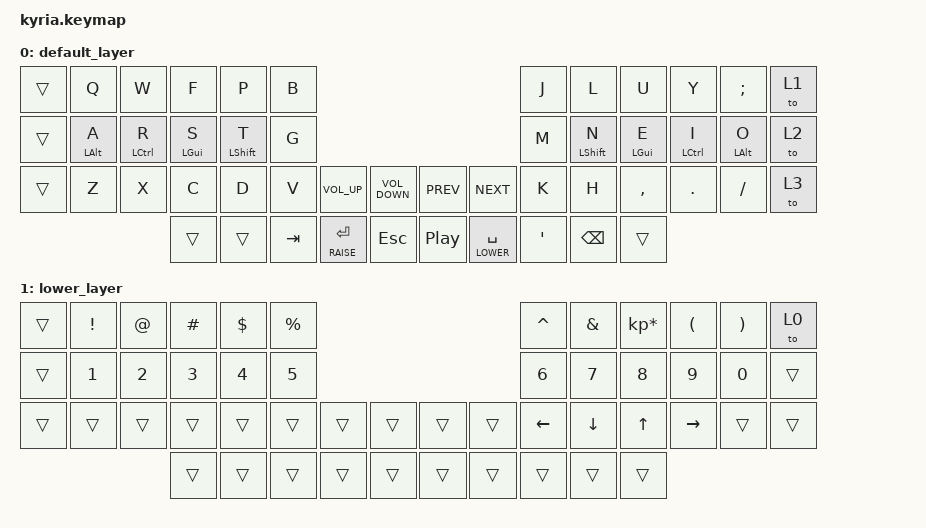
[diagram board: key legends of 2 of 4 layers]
#include <behaviors.dtsi>
#include <dt-bindings/zmk/keys.h>
#include <dt-bindings/zmk/bt.h>
#include <dt-bindings/zmk/outputs.h>
#include <dt-bindings/zmk/rgb.h>
#include <dt-bindings/zmk/ext_power.h>

#define DEFAULT 0
#define LOWER   1
#define RAISE   2
#define SETTINGS 3

# define BT(n) BT_SEL n

/ {
    behaviors {
        hm: homerow_mods {
            compatible = "zmk,behavior-hold-tap";
            label = "HOMEROW_MODS";
            #binding-cells = <2>;
            tapping_term_ms = <145>;
            flavor = "tap-preferred";
            bindings = <&kp>, <&kp>;
        };
    };

    combos {
        compatible = "zmk,combos";
        combo_bracket_curly_open {
            timeout-ms = <50>;
            key-positions = <14 15>;
            bindings = <&kp LBRC>;
        };
        // st is a bit too common as an inward roll to use for a combo
        combo_bracket_curly_close {
            timeout-ms = <50>;
            key-positions = <15 16>;
            bindings = <&kp RBRC>;
        };
    };

	keymap {
		compatible = "zmk,keymap";

		default_layer {
// ---------------------------------------------------------------------------------------------------------------------------------
// |  TAB  |  Q  |  W  |  F   |  P   |  B   |                                          |  J   |  L    |  U    |  Y   |   P   | ";"  |
// |  CTL  |  A  |  R  |  S   |  T   |  G   |                                          |  M   |  N    |  E    |  I   |   O   |   '  |
// | SHIFT |  Z  |  X  |  C   |  D   |  V   | L SHIFT | L SHIFT |  | L SHIFT | L SHIFT |  K   |  H    |  ,    |  .   |   /   | CTRL |
//                     | DEL  | GUI  | RET  |  SPACE  |  LOWER  |  |  RAISE  |  SPACE  | TAB  | BSPC  | R-ALT |
			bindings = <
	&trans  &kp Q       &kp W           &kp F       &kp P           &kp B                                                                           &kp J       &kp L       &kp U       &kp Y       &kp SEMI    &to 1
	&trans  &hm LALT A  &hm LCTRL R     &hm LGUI S  &hm LSHFT T     &kp G                                                                           &kp M       &hm LSHFT N &hm LGUI E  &hm LCTRL I &hm LALT O  &to 2
	&trans  &kp Z       &kp X           &kp C       &kp D           &kp V           &kp C_VOL_UP    &kp C_VOLUME_DOWN   &kp C_PREV  &kp C_NEXT      &kp K       &kp H       &kp COMMA   &kp DOT     &kp FSLH    &to 3
                                        &trans      &trans          &kp TAB         &lt RAISE RET   &kp ESC             &kp C_PP    &lt LOWER SPACE &kp SQT     &kp BSPC    &trans
			>;

            sensor-bindings = <&inc_dec_kp C_VOL_UP C_VOL_DN &inc_dec_kp PG_UP PG_DN>;
		};

		lower_layer {
// ---------------------------------------------------------------------------------------------------------------------------------
// |    |  !  |  @  |  #   |   $  |   %  |                 ~                    |  ^   |  &    |  * | (  |  )   |      |
// |    |  1  |  2  |  3   |  4   |  5   |                                      |  6   |  7    | 8  | 9  |  0   |      |
// |    |     |     |      |      |      |                                      |  ⬅   |  ⬇    | ⬆  | ➡  |      |      |
//                  |      |      |      |      |        |  |      |      |     |      |       |

// TODO: rearrange numbers to numpad layout
			bindings = <
    &trans &kp EXCL &kp AT  &kp HASH    &kp DLLR    &kp PRCNT                               &kp CARET   &kp AMPS    &kp KP_MULTIPLY &kp LPAR    &kp RPAR    &to 0
	&trans &kp N1   &kp N2  &kp N3      &kp N4      &kp N5                                  &kp N6      &kp N7      &kp N8          &kp N9      &kp N0      &trans
	&trans &trans   &trans  &trans      &trans      &trans    &trans &trans &trans &trans   &kp LEFT    &kp DOWN    &kp UP          &kp RIGHT  &trans       &trans
	                        &trans      &trans      &trans    &trans &trans &trans &trans   &trans      &trans      &trans
			>;
		};
        
		raise_layer {
// ---------------------------------------------------------------------------------------------------------------------------------
// |      |     |     |     |     |     |                 ~            |     |     |     |     |     |      |
// | CTRL |     |     |     |     |     |                 ~            |  -  |  =  |  {  |  }  | "|" |  `   |
// | SHFT |     |     |     |     |     |      |        | ~ |     |    |  _  |  +  |  [  |  ]  |  \  |  ~   | // TODO: Fix this row when &mkp is committed
//                 |      |      |      |      |        | ~ |     |    |     |     |     |
			bindings = <
    &trans   &kp EXCL &kp AT   &kp HASH &kp DLLR  &kp PRCNT                                 &kp CARET   &kp AMPS  &trans     &kp LPAR &kp RPAR &trans
    &kp BSLH &kp PLUS &kp LBRC &kp RBRC &kp TILDE &kp UNDER                                 &kp MINUS   &kp EQUAL &kp LBKT  &kp RBKT &kp PIPE &to 0
	&kp F1   &kp F2   &kp F3   &kp F4   &kp F5    &kp F6    &trans &trans &trans &trans     &kp F7      &kp F8    &kp F9    &kp F10  &kp F11  &kp F12
                               &trans   &to 3     &trans    &trans &trans &trans &kp GRAVE  &trans      &trans    &trans    &trans   &trans 
			>;
		};

        settings_layer {
        bindings = <
	&reset &bt BT(0) &bt BT(1) &bt BT(2)  &bt BT(3) &bt BT(4)                                  &ext_power EP_OFF &kp HOME  &bt BT_CLR  &kp END   &trans    &reset
	&out OUT_BLE  &out OUT_USB  &trans &trans &trans &trans &trans &trans &trans &trans &trans &trans
	&to 0  &trans &trans &trans &trans &trans &trans &trans &trans &trans &trans &trans &trans &trans &trans &to 0
	&trans &trans &trans &trans &trans &trans &trans &trans &trans &trans
            >;
        };
	};
};

